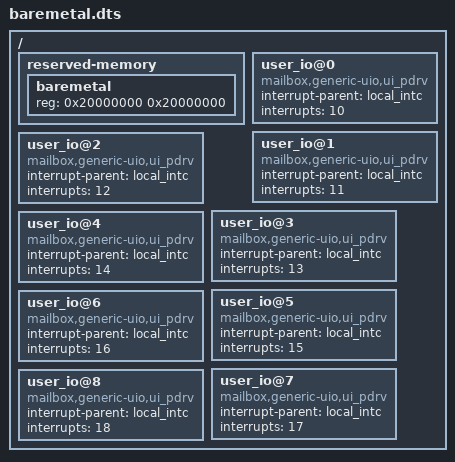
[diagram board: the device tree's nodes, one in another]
#include "bcm2709-rpi-2-b.dts"

/ {
	reserved-memory {
		#address-cells = <1>;
		#size-cells = <1>;
		ranges;

		// reserve memory for baremetal application
		baremetal {
			reg = <0x20000000 0x20000000>;
		};
	};

    user_io@0 {
        compatible = "mailbox,generic-uio,ui_pdrv";
        status = "okay";
        interrupt-parent = <&local_intc>;
        interrupts = <10>;
    };

    user_io@1 {
        compatible = "mailbox,generic-uio,ui_pdrv";
        status = "okay";
        interrupt-parent = <&local_intc>;
        interrupts = <11>;
    };

    user_io@2 {
        compatible = "mailbox,generic-uio,ui_pdrv";
        status = "okay";
        interrupt-parent = <&local_intc>;
        interrupts = <12>;
    };

    user_io@3 {
        compatible = "mailbox,generic-uio,ui_pdrv";
        status = "okay";
        interrupt-parent = <&local_intc>;
        interrupts = <13>;
    };

    user_io@4 {
        compatible = "mailbox,generic-uio,ui_pdrv";
        status = "okay";
        interrupt-parent = <&local_intc>;
        interrupts = <14>;
    };

    user_io@5 {
        compatible = "mailbox,generic-uio,ui_pdrv";
        status = "okay";
        interrupt-parent = <&local_intc>;
        interrupts = <15>;
    };

    user_io@6 {
        compatible = "mailbox,generic-uio,ui_pdrv";
        status = "okay";
        interrupt-parent = <&local_intc>;
        interrupts = <16>;
    };

    user_io@7 {
        compatible = "mailbox,generic-uio,ui_pdrv";
        status = "okay";
        interrupt-parent = <&local_intc>;
        interrupts = <17>;
    };

    user_io@8 {
        compatible = "mailbox,generic-uio,ui_pdrv";
        status = "okay";
        interrupt-parent = <&local_intc>;
        interrupts = <18>;
    };
};
